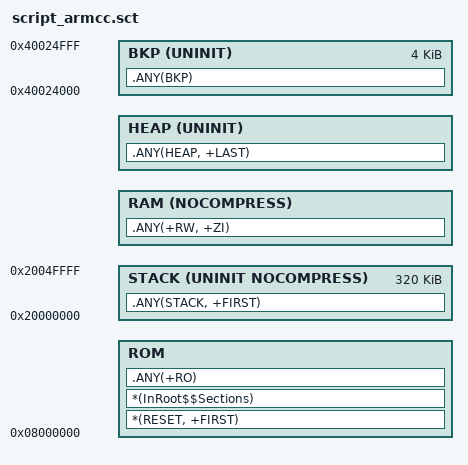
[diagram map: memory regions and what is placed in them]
#! armcc -E

/*******************************************************************************
@file     stm32f7xx.sct
@author   Rajmund Szymanski
@date     03.03.2016
@brief    Scatter file for STM32F746NG device with 1024KB FLASH and 320KB RAM
*******************************************************************************/

#define __rom_start 0x08000000
#define __rom_size  0x00100000
#define __rom_end  (__rom_start+__rom_size)
#define __ram_start 0x20000000
#define __ram_size  0x00050000
#define __ram_end  (__ram_start+__ram_size)
#define __bkp_start 0x40024000
#define __bkp_size  0x00001000
#define __bkp_end  (__bkp_start+__bkp_size)

FLASH __rom_start __rom_size
{
	ROM +0
	{
		*(RESET, +FIRST)
		*(InRoot$$Sections)
		.ANY(+RO)
	}

	BKP __bkp_start UNINIT __bkp_size
	{
		.ANY(BKP)
	}

	STACK __ram_start UNINIT NOCOMPRESS __ram_size
	{
		.ANY(STACK, +FIRST)
	}
	
	RAM ALIGNEXPR(+0, 8) NOCOMPRESS
	{
		.ANY(+RW, +ZI)
	}

	HEAP ALIGNEXPR(+0, 8) UNINIT
	{
		.ANY(HEAP, +LAST)
	}
}
